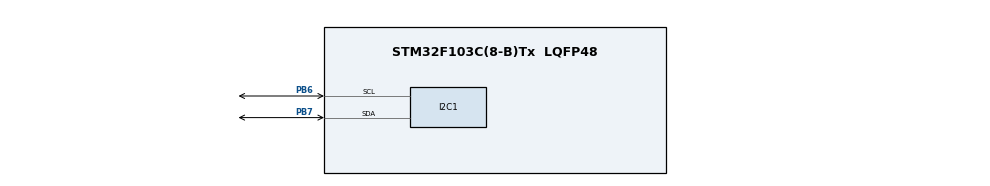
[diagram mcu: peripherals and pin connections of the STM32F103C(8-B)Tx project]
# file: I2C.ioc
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Mcu.Family=STM32F1
Mcu.Name=STM32F103C(8-B)Tx
Mcu.Package=LQFP48
NVIC.PriorityGroup=NVIC_PRIORITYGROUP_4
PA13.Mode=Serial_Wire
PA13.Signal=SYS_JTMS-SWDIO
PA14.Mode=Serial_Wire
PA14.Signal=SYS_JTCK-SWCLK
PB6.Mode=I2C
PB6.Signal=I2C1_SCL
PB7.Mode=I2C
PB7.Signal=I2C1_SDA
ProjectManager.HeapSize=0x200
ProjectManager.StackSize=0x400
ProjectManager.TargetToolchain=STM32CubeIDE
RCC.APB1Freq_Value=8000000
RCC.APB2Freq_Value=8000000
board=custom

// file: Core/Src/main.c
/* USER CODE BEGIN Header */
/**
  ******************************************************************************
  * @file           : main.c
  * @brief          : Main program body
  ******************************************************************************
  * @attention
  *
  * Copyright (c) 2026 STMicroelectronics.
  * All rights reserved.
  *
  * This software is licensed under terms that can be found in the LICENSE file
  * in the root directory of this software component.
  * If no LICENSE file comes with this software, it is provided AS-IS.
  *
  ******************************************************************************
  */
/* USER CODE END Header */
#include "main.h"

I2C_HandleTypeDef hi2c1;

void SystemClock_Config(void);
static void MX_GPIO_Init(void);
static void MX_I2C1_Init(void);

/* USER CODE BEGIN 0 */
 // 0x68 <<1
#define ADD 0xD0

uint16_t ax = 0, ay = 0, az = 0, gx = 0, gy = 0, gz= 0 ;
float AX, AY, AZ, GX, GY,GZ ;
void MPU6050Init(){
	uint8_t check;
	uint8_t mData;
	HAL_I2C_Mem_Read(&hi2c1, ADD, 0x75, 1, &check, 1, 1000 );
	if (check == 0x68){
		mData = 0x00;
		HAL_I2C_Mem_Write(&hi2c1, ADD, 0x6B, 1, &mData, 1, 1000 );
		mData = 0x07;
		HAL_I2C_Mem_Write(&hi2c1, ADD, 0x19, 1, &mData, 1, 1000 );
		mData = 0x00;
		HAL_I2C_Mem_Write(&hi2c1, ADD, 0x1B, 1, &mData, 1, 1000 );
		mData = 0x00;
		HAL_I2C_Mem_Write(&hi2c1, ADD, 0x1C, 1, &mData, 1, 1000 );
	}
}

void MPU6050ReadG(void){
	uint8_t dataG[6];
	HAL_I2C_Mem_Read(&hi2c1, ADD, 0x43, 1, dataG, 6, 1000 );
	gx = (uint16_t)(dataG[0]<<8 | dataG[1]);
	gy = (uint16_t)(dataG[2]<<8 | dataG[3]);
	gz = (uint16_t)(dataG[4]<<8 | dataG[5]);
	GX = (float)gx/131.0;
	GY = (float)gy/131.0;
	GZ = (float)gz/131.0;
}
void MPU6050ReadA(void){
	uint8_t dataA[6];
	HAL_I2C_Mem_Read(&hi2c1, ADD, 0x3B, 1, dataA, 6, 1000 );
	ax = (uint16_t)(dataA[0]<<8 | dataA[1]);
	ay = (uint16_t)(dataA[2]<<8 | dataA[3]);
	az = (uint16_t)(dataA[4]<<8 | dataA[5]);
	AX= (float)ax/16384.0;
	AY= (float)ay/16384.0;
	AZ= (float)az/16384.0;
}
/* USER CODE END 0 */

int main(void)
{

  /* MCU Configuration--------------------------------------------------------*/

  /* Reset of all peripherals, Initializes the Flash interface and the Systick. */
  HAL_Init();

  /* Configure the system clock */
  SystemClock_Config();

  /* Initialize all configured peripherals */
  MX_GPIO_Init();
  MX_I2C1_Init();
  /* USER CODE BEGIN 2 */
  MPU6050Init();
  /* USER CODE END 2 */

  /* Infinite loop */
  while (1)
  {
	  MPU6050ReadG();
	  MPU6050ReadA();
	  HAL_Delay(100);
  }
}

void SystemClock_Config(void)
{
  RCC_OscInitTypeDef RCC_OscInitStruct = {0};
  RCC_ClkInitTypeDef RCC_ClkInitStruct = {0};

  /** Initializes the RCC Oscillators according to the specified parameters
  * in the RCC_OscInitTypeDef structure.
  */
  RCC_OscInitStruct.OscillatorType = RCC_OSCILLATORTYPE_HSI;
  RCC_OscInitStruct.HSIState = RCC_HSI_ON;
  RCC_OscInitStruct.HSICalibrationValue = RCC_HSICALIBRATION_DEFAULT;
  RCC_OscInitStruct.PLL.PLLState = RCC_PLL_NONE;
  if (HAL_RCC_OscConfig(&RCC_OscInitStruct) != HAL_OK)
  {
    Error_Handler();
  }

  /** Initializes the CPU, AHB and APB buses clocks
  */
  RCC_ClkInitStruct.ClockType = RCC_CLOCKTYPE_HCLK|RCC_CLOCKTYPE_SYSCLK
                              |RCC_CLOCKTYPE_PCLK1|RCC_CLOCKTYPE_PCLK2;
  RCC_ClkInitStruct.SYSCLKSource = RCC_SYSCLKSOURCE_HSI;
  RCC_ClkInitStruct.AHBCLKDivider = RCC_SYSCLK_DIV1;
  RCC_ClkInitStruct.APB1CLKDivider = RCC_HCLK_DIV1;
  RCC_ClkInitStruct.APB2CLKDivider = RCC_HCLK_DIV1;

  if (HAL_RCC_ClockConfig(&RCC_ClkInitStruct, FLASH_LATENCY_0) != HAL_OK)
  {
    Error_Handler();
  }
}

static void MX_I2C1_Init(void)
{

  hi2c1.Instance = I2C1;
  hi2c1.Init.ClockSpeed = 100000;
  hi2c1.Init.DutyCycle = I2C_DUTYCYCLE_2;
  hi2c1.Init.OwnAddress1 = 0;
  hi2c1.Init.AddressingMode = I2C_ADDRESSINGMODE_7BIT;
  hi2c1.Init.DualAddressMode = I2C_DUALADDRESS_DISABLE;
  hi2c1.Init.OwnAddress2 = 0;
  hi2c1.Init.GeneralCallMode = I2C_GENERALCALL_DISABLE;
  hi2c1.Init.NoStretchMode = I2C_NOSTRETCH_DISABLE;
  if (HAL_I2C_Init(&hi2c1) != HAL_OK)
  {
    Error_Handler();
  }

}

static void MX_GPIO_Init(void)
{

  /* GPIO Ports Clock Enable */
  __HAL_RCC_GPIOA_CLK_ENABLE();
  __HAL_RCC_GPIOB_CLK_ENABLE();

}

void Error_Handler(void)
{
  __disable_irq();
  while (1)
  {
  }
}
